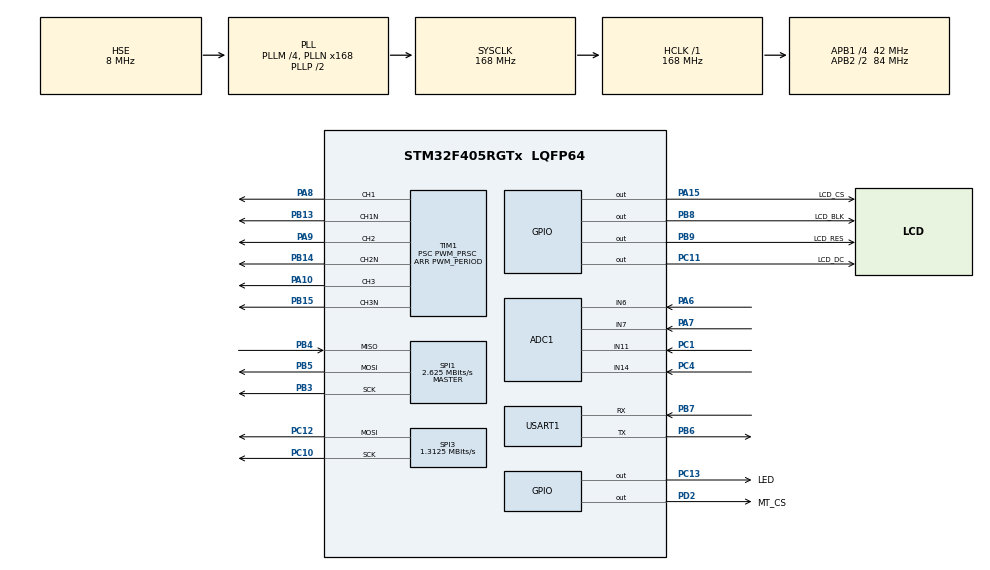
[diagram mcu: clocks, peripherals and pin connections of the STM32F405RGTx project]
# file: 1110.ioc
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ADC1.Channel-0\#ChannelRegularConversion=ADC_CHANNEL_11
ADC1.Channel-1\#ChannelInjectedConversion=ADC_CHANNEL_6
ADC1.Channel-2\#ChannelInjectedConversion=ADC_CHANNEL_7
ADC1.Channel-3\#ChannelInjectedConversion=ADC_CHANNEL_14
ADC1.ContinuousConvMode=ENABLE
ADC1.DataAlign=ADC_DATAALIGN_RIGHT
ADC1.ExternalTrigInjecConv=ADC_EXTERNALTRIGINJECCONV_T1_CC4
ADC1.InjNumberOfConversion=3
ADC1.InjectedOffset-1\#ChannelInjectedConversion=0
ADC1.InjectedOffset-2\#ChannelInjectedConversion=0
ADC1.InjectedOffset-3\#ChannelInjectedConversion=0
ADC1.InjectedRank-1\#ChannelInjectedConversion=1
ADC1.InjectedRank-2\#ChannelInjectedConversion=2
ADC1.InjectedRank-3\#ChannelInjectedConversion=3
ADC1.NbrOfConversionFlag=1
ADC1.Rank-0\#ChannelRegularConversion=1
ADC1.SamplingTime-0\#ChannelRegularConversion=ADC_SAMPLETIME_28CYCLES
ADC1.SamplingTime-1\#ChannelInjectedConversion=ADC_SAMPLETIME_15CYCLES
ADC1.SamplingTime-2\#ChannelInjectedConversion=ADC_SAMPLETIME_15CYCLES
ADC1.SamplingTime-3\#ChannelInjectedConversion=ADC_SAMPLETIME_15CYCLES
ADC1.ScanConvMode=ENABLE
ADC1.master=1
Dma.ADC1.0.Direction=DMA_PERIPH_TO_MEMORY
Dma.ADC1.0.FIFOMode=DMA_FIFOMODE_DISABLE
Dma.ADC1.0.Instance=DMA2_Stream0
Dma.ADC1.0.MemDataAlignment=DMA_MDATAALIGN_WORD
Dma.ADC1.0.MemInc=DMA_MINC_ENABLE
Dma.ADC1.0.Mode=DMA_CIRCULAR
Dma.ADC1.0.PeriphDataAlignment=DMA_PDATAALIGN_WORD
Dma.ADC1.0.PeriphInc=DMA_PINC_DISABLE
Dma.ADC1.0.Priority=DMA_PRIORITY_HIGH
Dma.Request0=ADC1
Mcu.Family=STM32F4
Mcu.Name=STM32F405RGTx
Mcu.Package=LQFP64
Mcu.UserConstants=REP_RATE,1;CKTIM,168000000;DEADTIME_NS,1000;ALIGNMENT_ANGLE,0;POLE_PAIR_NUM,14;PWM_PRSC,0;ICx_FILTER,8;PWM_FREQ,10000;COUNTER_RESET,(ALIGNMENT_ANGLE*4*ENCODER_PPR/360-1)/POLE_PAIR_NUM;PWM_PERIOD,CKTIM/(2*PWM_FREQ*(PWM_PRSC+1));DEADTIME,CKTIM/1000000/2*DEADTIME_NS/1000;ENCODER_PPR,2500
NVIC.ADC_IRQn=true\:1\:0\:true\:false\:true\:true\:true\:true
NVIC.DMA2_Stream0_IRQn=true\:1\:0\:true\:false\:true\:false\:true\:true
NVIC.PriorityGroup=NVIC_PRIORITYGROUP_4
NVIC.SPI1_IRQn=true\:2\:0\:true\:false\:true\:true\:true\:true
NVIC.TIM5_IRQn=true\:4\:0\:true\:false\:true\:true\:true\:true
PA10.Signal=S_TIM1_CH3
PA13.Mode=Serial_Wire
PA13.Signal=SYS_JTMS-SWDIO
PA14.Mode=Serial_Wire
PA14.Signal=SYS_JTCK-SWCLK
PA15.GPIO_Label=LCD_CS
PA15.GPIO_Speed=GPIO_SPEED_FREQ_HIGH
PA15.Signal=GPIO_Output
PA6.Signal=ADCx_IN6
PA7.Signal=ADCx_IN7
PA8.Signal=S_TIM1_CH1
PA9.Signal=S_TIM1_CH2
PB13.Mode=PWM Generation1 CH1 CH1N
PB13.Signal=TIM1_CH1N
PB14.Mode=PWM Generation2 CH2 CH2N
PB14.Signal=TIM1_CH2N
PB15.Mode=PWM Generation3 CH3 CH3N
PB15.Signal=TIM1_CH3N
PB3.Mode=Full_Duplex_Master
PB3.Signal=SPI1_SCK
PB4.Mode=Full_Duplex_Master
PB4.Signal=SPI1_MISO
PB5.Mode=Full_Duplex_Master
PB5.Signal=SPI1_MOSI
PB6.Mode=Asynchronous
PB6.Signal=USART1_TX
PB7.Mode=Asynchronous
PB7.Signal=USART1_RX
PB8.GPIO_Label=LCD_BLK
PB8.GPIO_Speed=GPIO_SPEED_FREQ_HIGH
PB8.Signal=GPIO_Output
PB9.GPIO_Label=LCD_RES
PB9.GPIO_Speed=GPIO_SPEED_FREQ_HIGH
PB9.Signal=GPIO_Output
PC1.Signal=ADCx_IN11
PC10.Mode=TX_Only_Simplex_Unidirect_Master
PC10.Signal=SPI3_SCK
PC11.GPIO_Label=LCD_DC
PC11.GPIO_Speed=GPIO_SPEED_FREQ_HIGH
PC11.PinState=GPIO_PIN_RESET
PC11.Signal=GPIO_Output
PC12.Mode=TX_Only_Simplex_Unidirect_Master
PC12.Signal=SPI3_MOSI
PC13-ANTI_TAMP.GPIO_Label=LED
PC13-ANTI_TAMP.Signal=GPIO_Output
PC4.Signal=ADCx_IN14
PD2.GPIO_Label=MT_CS
PD2.PinState=GPIO_PIN_SET
PD2.Signal=GPIO_Output
PH0-OSC_IN.Mode=HSE-External-Oscillator
PH0-OSC_IN.Signal=RCC_OSC_IN
PH1-OSC_OUT.Mode=HSE-External-Oscillator
PH1-OSC_OUT.Signal=RCC_OSC_OUT
ProjectManager.HeapSize=0x200
ProjectManager.StackSize=0x400
ProjectManager.TargetToolchain=MDK-ARM V5.32
RCC.48MHZClocksFreq_Value=84000000
RCC.AHBFreq_Value=168000000
RCC.APB1CLKDivider=RCC_HCLK_DIV4
RCC.APB1Freq_Value=42000000
RCC.APB1TimFreq_Value=84000000
RCC.APB2CLKDivider=RCC_HCLK_DIV2
RCC.APB2Freq_Value=84000000
RCC.APB2TimFreq_Value=168000000
RCC.CortexFreq_Value=168000000
RCC.HCLKFreq_Value=168000000
RCC.HSE_Timout=1000
RCC.HSE_VALUE=8000000
RCC.HSI_VALUE=16000000
RCC.LSE_VALUE=32768
RCC.PLLM=4
RCC.PLLN=168
RCC.PLLSourceVirtual=RCC_PLLSOURCE_HSE
RCC.SYSCLKFreq_VALUE=168000000
RCC.SYSCLKSource=RCC_SYSCLKSOURCE_PLLCLK
RCC.VCOOutputFreq_Value=336000000
SH.ADCx_IN11.0=ADC1_IN11,IN11
SH.ADCx_IN14.0=ADC1_IN14,IN14
SH.ADCx_IN6.0=ADC1_IN6,IN6
SH.ADCx_IN7.0=ADC1_IN7,IN7
SH.S_TIM1_CH1.0=TIM1_CH1,PWM Generation1 CH1 CH1N
SH.S_TIM1_CH2.0=TIM1_CH2,PWM Generation2 CH2 CH2N
SH.S_TIM1_CH3.0=TIM1_CH3,PWM Generation3 CH3 CH3N
SPI1.BaudRatePrescaler=SPI_BAUDRATEPRESCALER_32
SPI1.CLKPhase=SPI_PHASE_2EDGE
SPI1.CalculateBaudRate=2.625 MBits/s
SPI1.DataSize=SPI_DATASIZE_16BIT
SPI1.Direction=SPI_DIRECTION_2LINES
SPI1.Mode=SPI_MODE_MASTER
SPI1.VirtualType=VM_MASTER
SPI3.BaudRatePrescaler=SPI_BAUDRATEPRESCALER_32
SPI3.CLKPolarity=SPI_POLARITY_HIGH
SPI3.CalculateBaudRate=1.3125 MBits/s
SPI3.DataSize=SPI_DATASIZE_8BIT
SPI3.Direction=SPI_DIRECTION_2LINES
SPI3.Mode=SPI_MODE_MASTER
SPI3.VirtualType=VM_MASTER
TIM1.Channel-PWM\ Generation1\ CH1\ CH1N=TIM_CHANNEL_1
TIM1.Channel-PWM\ Generation2\ CH2\ CH2N=TIM_CHANNEL_2
TIM1.Channel-PWM\ Generation3\ CH3\ CH3N=TIM_CHANNEL_3
TIM1.Channel-PWM\ Generation4\ No\ Output=TIM_CHANNEL_4
TIM1.ClockDivision=TIM_CLOCKDIVISION_DIV2
TIM1.CounterMode=TIM_COUNTERMODE_CENTERALIGNED1
TIM1.DeadTime=DEADTIME
TIM1.LockLevel=TIM_LOCKLEVEL_1
TIM1.OCMode_PWM-PWM\ Generation4\ No\ Output=TIM_OCMODE_PWM2
TIM1.OCNIdleState_1=TIM_OCNIDLESTATE_RESET
TIM1.OCNIdleState_2=TIM_OCNIDLESTATE_RESET
TIM1.OCNIdleState_3=TIM_OCNIDLESTATE_RESET
TIM1.OCNPolarity_1=TIM_OCNPOLARITY_HIGH
TIM1.OCNPolarity_2=TIM_OCNPOLARITY_HIGH
TIM1.OCNPolarity_3=TIM_OCNPOLARITY_HIGH
TIM1.OCPolarity_1=TIM_OCPOLARITY_HIGH
TIM1.OCPolarity_2=TIM_OCPOLARITY_HIGH
TIM1.OCPolarity_3=TIM_OCPOLARITY_HIGH
TIM1.OffStateIDLEMode=TIM_OSSI_ENABLE
TIM1.OffStateRunMode=TIM_OSSR_ENABLE
TIM1.Period=PWM_PERIOD
TIM1.Prescaler=PWM_PRSC
TIM1.Pulse-PWM\ Generation4\ No\ Output=PWM_PERIOD-1
TIM1.RepetitionCounter=REP_RATE
TIM1.TIM_MasterOutputTrigger=TIM_TRGO_OC4REF
TIM5.Period=10000-1
TIM5.Prescaler=84-1
USART1.VirtualMode=VM_ASYNC
VP_TIM1_VS_ClockSourceINT.Mode=Internal
VP_TIM1_VS_no_output4.Mode=PWM Generation4 No Output
VP_TIM5_VS_ClockSourceINT.Mode=Internal
board=custom

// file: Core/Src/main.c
/* USER CODE BEGIN Header */
/**
  ******************************************************************************
  * @file           : main.c
  * @brief          : Main program body
  ******************************************************************************
  * @attention
  *
  * <h2><center>&copy; Copyright (c) 2021 STMicroelectronics.
  * All rights reserved.</center></h2>
  *
  * This software component is licensed by ST under BSD 3-Clause license,
  * the "License"; You may not use this file except in compliance with the
  * License. You may obtain a copy of the License at:
  *                        opensource.org/licenses/BSD-3-Clause
  *
  ******************************************************************************
  */
/* USER CODE END Header */
#include "main.h"
#include "adc.h"
#include "dma.h"
#include "spi.h"
#include "tim.h"
#include "usart.h"
#include "gpio.h"

/* USER CODE BEGIN Includes */

#include "motor.h"
#include "Sensor_SPI.h"
#include "user_fcn.h"

/*
每次重新生成代码后，需要修改f4xx_hal.h中的systick中断时间
*/

/* USER CODE END Includes */

void SystemClock_Config(void);

int main(void)
{

  /* MCU Configuration--------------------------------------------------------*/

  /* Reset of all peripherals, Initializes the Flash interface and the Systick. */
  HAL_Init();

  /* Configure the system clock */
  SystemClock_Config();

  /* Initialize all configured peripherals */
  MX_GPIO_Init();
  MX_TIM1_Init();
  MX_DMA_Init();
  MX_ADC1_Init();
  MX_SPI1_Init();
  MX_USART1_UART_Init();
  MX_SPI3_Init();
  MX_TIM5_Init();
  /* USER CODE BEGIN 2 */

	board_config();
	gui_init();

  /* USER CODE END 2 */

  /* Infinite loop */
  while (1)
  {

    /* USER CODE BEGIN 3 */

		dis_info_core();

  }
  /* USER CODE END 3 */
}

void SystemClock_Config(void)
{
  RCC_OscInitTypeDef RCC_OscInitStruct = {0};
  RCC_ClkInitTypeDef RCC_ClkInitStruct = {0};

  /** Configure the main internal regulator output voltage
  */
  __HAL_RCC_PWR_CLK_ENABLE();
  __HAL_PWR_VOLTAGESCALING_CONFIG(PWR_REGULATOR_VOLTAGE_SCALE1);

  /** Initializes the RCC Oscillators according to the specified parameters
  * in the RCC_OscInitTypeDef structure.
  */
  RCC_OscInitStruct.OscillatorType = RCC_OSCILLATORTYPE_HSE;
  RCC_OscInitStruct.HSEState = RCC_HSE_ON;
  RCC_OscInitStruct.PLL.PLLState = RCC_PLL_ON;
  RCC_OscInitStruct.PLL.PLLSource = RCC_PLLSOURCE_HSE;
  RCC_OscInitStruct.PLL.PLLM = 4;
  RCC_OscInitStruct.PLL.PLLN = 168;
  RCC_OscInitStruct.PLL.PLLP = RCC_PLLP_DIV2;
  RCC_OscInitStruct.PLL.PLLQ = 4;
  if (HAL_RCC_OscConfig(&RCC_OscInitStruct) != HAL_OK)
  {
    Error_Handler();
  }

  /** Initializes the CPU, AHB and APB buses clocks
  */
  RCC_ClkInitStruct.ClockType = RCC_CLOCKTYPE_HCLK|RCC_CLOCKTYPE_SYSCLK
                              |RCC_CLOCKTYPE_PCLK1|RCC_CLOCKTYPE_PCLK2;
  RCC_ClkInitStruct.SYSCLKSource = RCC_SYSCLKSOURCE_PLLCLK;
  RCC_ClkInitStruct.AHBCLKDivider = RCC_SYSCLK_DIV1;
  RCC_ClkInitStruct.APB1CLKDivider = RCC_HCLK_DIV4;
  RCC_ClkInitStruct.APB2CLKDivider = RCC_HCLK_DIV2;

  if (HAL_RCC_ClockConfig(&RCC_ClkInitStruct, FLASH_LATENCY_5) != HAL_OK)
  {
    Error_Handler();
  }
}

void Error_Handler(void)
{
  __disable_irq();
  while (1)
  {
  }
}
